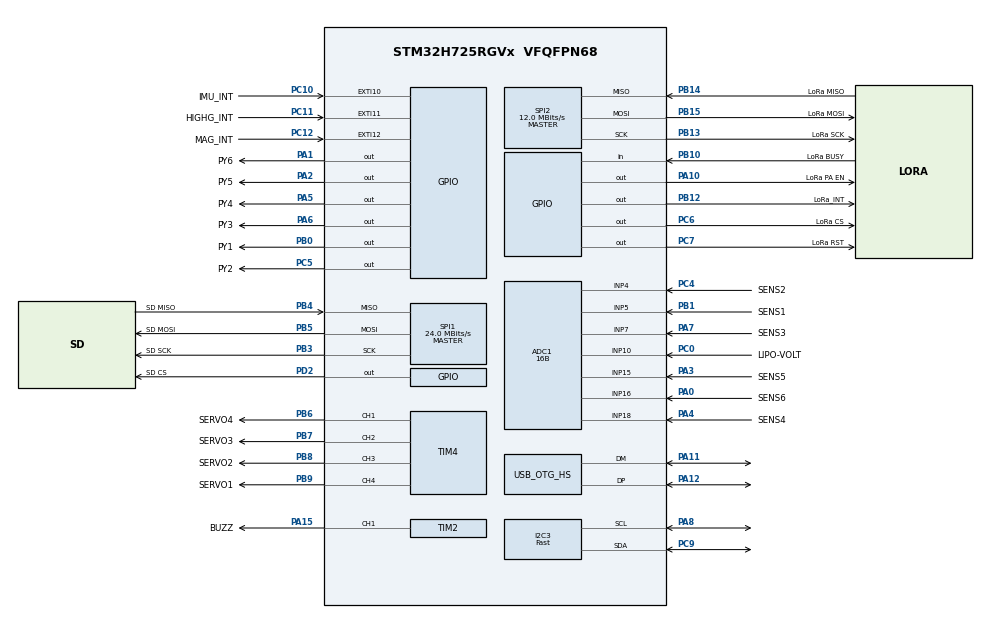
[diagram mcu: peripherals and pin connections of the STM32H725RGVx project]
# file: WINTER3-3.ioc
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ADC1.Channel-0\#ChannelRegularConversion=ADC_CHANNEL_10
ADC1.NbrOfConversionFlag=1
ADC1.OffsetNumber-0\#ChannelRegularConversion=ADC_OFFSET_NONE
ADC1.OffsetSignedSaturation-0\#ChannelRegularConversion=DISABLE
ADC1.Rank-0\#ChannelRegularConversion=1
ADC1.Resolution=ADC_RESOLUTION_16B
ADC1.SamplingTime-0\#ChannelRegularConversion=ADC_SAMPLETIME_64CYCLES_5
ADC1.master=1
CORTEX_M7.AccessPermission-Cortex_Memory_Protection_Unit_Region0_Settings=MPU_REGION_FULL_ACCESS
CORTEX_M7.AccessPermission-Cortex_Memory_Protection_Unit_Region1_Settings=MPU_REGION_FULL_ACCESS
CORTEX_M7.BaseAddress-Cortex_Memory_Protection_Unit_Region0_Settings=0x30000000
CORTEX_M7.BaseAddress-Cortex_Memory_Protection_Unit_Region1_Settings=0x38000000
CORTEX_M7.CPU_DCache=Enabled
CORTEX_M7.CPU_ICache=Enabled
CORTEX_M7.DisableExec-Cortex_Memory_Protection_Unit_Region0_Settings=MPU_INSTRUCTION_ACCESS_ENABLE
CORTEX_M7.Enable-Cortex_Memory_Protection_Unit_Region0_Settings=MPU_REGION_ENABLE
CORTEX_M7.Enable-Cortex_Memory_Protection_Unit_Region1_Settings=MPU_REGION_ENABLE
CORTEX_M7.MPU_Control=MPU_PRIVILEGED_DEFAULT
CORTEX_M7.Size-Cortex_Memory_Protection_Unit_Region0_Settings=MPU_REGION_SIZE_32KB
CORTEX_M7.Size-Cortex_Memory_Protection_Unit_Region1_Settings=MPU_REGION_SIZE_16KB
Dma.Request0=SPI1_TX
Dma.Request1=SPI1_RX
Dma.SPI1_RX.1.Direction=DMA_PERIPH_TO_MEMORY
Dma.SPI1_RX.1.EventEnable=DISABLE
Dma.SPI1_RX.1.FIFOMode=DMA_FIFOMODE_DISABLE
Dma.SPI1_RX.1.Instance=DMA1_Stream1
Dma.SPI1_RX.1.MemDataAlignment=DMA_MDATAALIGN_BYTE
Dma.SPI1_RX.1.MemInc=DMA_MINC_ENABLE
Dma.SPI1_RX.1.Mode=DMA_NORMAL
Dma.SPI1_RX.1.PeriphDataAlignment=DMA_PDATAALIGN_BYTE
Dma.SPI1_RX.1.PeriphInc=DMA_PINC_DISABLE
Dma.SPI1_RX.1.Polarity=HAL_DMAMUX_REQ_GEN_RISING
Dma.SPI1_RX.1.Priority=DMA_PRIORITY_HIGH
Dma.SPI1_RX.1.RequestNumber=1
Dma.SPI1_RX.1.SignalID=NONE
Dma.SPI1_RX.1.SyncEnable=DISABLE
Dma.SPI1_RX.1.SyncPolarity=HAL_DMAMUX_SYNC_NO_EVENT
Dma.SPI1_RX.1.SyncRequestNumber=1
Dma.SPI1_RX.1.SyncSignalID=NONE
Dma.SPI1_TX.0.Direction=DMA_MEMORY_TO_PERIPH
Dma.SPI1_TX.0.EventEnable=DISABLE
Dma.SPI1_TX.0.FIFOMode=DMA_FIFOMODE_DISABLE
Dma.SPI1_TX.0.Instance=DMA1_Stream0
Dma.SPI1_TX.0.MemDataAlignment=DMA_MDATAALIGN_BYTE
Dma.SPI1_TX.0.MemInc=DMA_MINC_ENABLE
Dma.SPI1_TX.0.Mode=DMA_NORMAL
Dma.SPI1_TX.0.PeriphDataAlignment=DMA_PDATAALIGN_BYTE
Dma.SPI1_TX.0.PeriphInc=DMA_PINC_DISABLE
Dma.SPI1_TX.0.Polarity=HAL_DMAMUX_REQ_GEN_RISING
Dma.SPI1_TX.0.Priority=DMA_PRIORITY_HIGH
Dma.SPI1_TX.0.RequestNumber=1
Dma.SPI1_TX.0.SignalID=NONE
Dma.SPI1_TX.0.SyncEnable=DISABLE
Dma.SPI1_TX.0.SyncPolarity=HAL_DMAMUX_SYNC_NO_EVENT
Dma.SPI1_TX.0.SyncRequestNumber=1
Dma.SPI1_TX.0.SyncSignalID=NONE
FATFS._FS_EXFAT=0
FATFS._FS_NORTC=1
FATFS._USE_EXPAND=1
FATFS._USE_LFN=2
I2C3.I2C_Speed_Mode=I2C_Fast
I2C3.Timing=0x00602173
Mcu.Family=STM32H7
Mcu.Name=STM32H725RGVx
Mcu.Package=VFQFPN68
NVIC.DMA1_Stream0_IRQn=true\:0\:0\:false\:false\:true\:false\:true\:true
NVIC.DMA1_Stream1_IRQn=true\:0\:0\:false\:false\:true\:false\:true\:true
NVIC.EXTI15_10_IRQn=true\:0\:0\:false\:false\:true\:true\:true\:true
NVIC.OTG_HS_EP1_IN_IRQn=true\:0\:0\:false\:false\:true\:true\:true\:true
NVIC.OTG_HS_EP1_OUT_IRQn=true\:0\:0\:false\:false\:true\:true\:true\:true
NVIC.OTG_HS_IRQn=true\:0\:0\:false\:false\:true\:false\:true\:true
NVIC.PriorityGroup=NVIC_PRIORITYGROUP_4
NVIC.SPI1_IRQn=true\:0\:0\:false\:false\:true\:false\:true\:true
PA0.GPIO_Label=SENS6
PA0.Mode=IN16-Single-Ended
PA0.Signal=ADC1_INP16
PA1.GPIO_Label=PY6
PA1.GPIO_PuPd=GPIO_NOPULL
PA1.Signal=GPIO_Output
PA10.GPIO_Label=LoRa PA EN
PA10.Signal=GPIO_Output
PA11.Mode=Device_Only_FS
PA11.Signal=USB_OTG_HS_DM
PA12.Mode=Device_Only_FS
PA12.Signal=USB_OTG_HS_DP
PA13(JTMS/SWDIO).GPIO_Label=SWDIO
PA13(JTMS/SWDIO).Mode=Serial_Wire
PA13(JTMS/SWDIO).Signal=DEBUG_JTMS-SWDIO
PA14(JTCK/SWCLK).GPIO_Label=SWCLK
PA14(JTCK/SWCLK).Mode=Serial_Wire
PA14(JTCK/SWCLK).Signal=DEBUG_JTCK-SWCLK
PA15(JTDI).GPIO_Label=BUZZ
PA15(JTDI).GPIO_Speed=GPIO_SPEED_FREQ_VERY_HIGH
PA15(JTDI).Signal=S_TIM2_CH1_ETR
PA2.GPIO_Label=PY5
PA2.GPIO_PuPd=GPIO_NOPULL
PA2.Signal=GPIO_Output
PA3.GPIO_Label=SENS5
PA3.Signal=ADCx_INP15
PA4.GPIO_Label=SENS4
PA4.Signal=ADCx_INP18
PA5.GPIO_Label=PY4
PA5.GPIO_PuPd=GPIO_NOPULL
PA5.Signal=GPIO_Output
PA6.GPIO_Label=PY3
PA6.GPIO_PuPd=GPIO_NOPULL
PA6.Signal=GPIO_Output
PA7.GPIO_Label=SENS3
PA7.Signal=ADCx_INP7
PA8.GPIO_Speed=GPIO_SPEED_FREQ_HIGH
PA8.Mode=I2C
PA8.Signal=I2C3_SCL
PB0.GPIO_Label=PY1
PB0.GPIO_PuPd=GPIO_NOPULL
PB0.Signal=GPIO_Output
PB1.GPIO_Label=SENS1
PB1.Signal=ADCx_INP5
PB10.GPIO_Label=LoRa BUSY
PB10.Signal=GPIO_Input
PB12.GPIO_Label=LoRa_INT
PB12.Signal=GPIO_Output
PB13.GPIO_Label=LoRa SCK
PB13.GPIO_Speed=GPIO_SPEED_FREQ_HIGH
PB13.Mode=Full_Duplex_Master
PB13.Signal=SPI2_SCK
PB14.GPIO_Label=LoRa MISO
PB14.GPIO_Speed=GPIO_SPEED_FREQ_HIGH
PB14.Mode=Full_Duplex_Master
PB14.Signal=SPI2_MISO
PB15.GPIO_Label=LoRa MOSI
PB15.GPIO_Speed=GPIO_SPEED_FREQ_HIGH
PB15.Mode=Full_Duplex_Master
PB15.Signal=SPI2_MOSI
PB3(JTDO/TRACESWO).GPIO_Label=SD SCK
PB3(JTDO/TRACESWO).GPIO_Speed=GPIO_SPEED_FREQ_HIGH
PB3(JTDO/TRACESWO).Mode=Full_Duplex_Master
PB3(JTDO/TRACESWO).Signal=SPI1_SCK
PB4(NJTRST).GPIO_Label=SD MISO
PB4(NJTRST).GPIO_Speed=GPIO_SPEED_FREQ_HIGH
PB4(NJTRST).Mode=Full_Duplex_Master
PB4(NJTRST).Signal=SPI1_MISO
PB5.GPIO_Label=SD MOSI
PB5.GPIO_Speed=GPIO_SPEED_FREQ_HIGH
PB5.Mode=Full_Duplex_Master
PB5.Signal=SPI1_MOSI
PB6.GPIO_Label=SERVO4
PB6.Signal=S_TIM4_CH1
PB7.GPIO_Label=SERVO3
PB7.Signal=S_TIM4_CH2
PB8.GPIO_Label=SERVO2
PB8.Signal=S_TIM4_CH3
PB9.GPIO_Label=SERVO1
PB9.Signal=S_TIM4_CH4
PC0.GPIO_Label=LIPO-VOLT
PC0.Signal=ADCx_INP10
PC10.GPIO_Label=IMU_INT
PC10.Signal=GPXTI10
PC11.GPIO_Label=HIGHG_INT
PC11.Signal=GPXTI11
PC12.GPIO_Label=MAG_INT
PC12.Signal=GPXTI12
PC4.GPIO_Label=SENS2
PC4.Signal=ADCx_INP4
PC5.GPIO_Label=PY2
PC5.GPIO_PuPd=GPIO_NOPULL
PC5.Signal=GPIO_Output
PC6.GPIO_Label=LoRa CS
PC6.GPIO_PuPd=GPIO_NOPULL
PC6.Signal=GPIO_Output
PC7.GPIO_Label=LoRa RST
PC7.Signal=GPIO_Output
PC9.GPIO_Speed=GPIO_SPEED_FREQ_HIGH
PC9.Mode=I2C
PC9.Signal=I2C3_SDA
PD2.GPIO_Label=SD CS
PD2.GPIO_PuPd=GPIO_NOPULL
PD2.GPIO_Speed=GPIO_SPEED_FREQ_HIGH
PD2.PinState=GPIO_PIN_SET
PD2.Signal=GPIO_Output
PH0-OSC_IN.Mode=HSE-External-Clock-Source
PH0-OSC_IN.Signal=RCC_OSC_IN
ProjectManager.HeapSize=0x200
ProjectManager.StackSize=0x400
ProjectManager.TargetToolchain=Makefile
RCC.ADCFreq_Value=48000000
RCC.APB1Freq_Value=120000000
RCC.APB2Freq_Value=120000000
RCC.APB3Freq_Value=120000000
RCC.APB4Freq_Value=120000000
RCC.CortexFreq_Value=240000000
RCC.D1PPRE=RCC_APB3_DIV2
RCC.D2PPRE1=RCC_APB1_DIV2
RCC.D2PPRE2=RCC_APB2_DIV2
RCC.D3PPRE=RCC_APB4_DIV2
RCC.DIVM1=2
RCC.DIVM2=2
RCC.DIVM3=2
RCC.DIVN1=20
RCC.DIVN2=16
RCC.DIVN3=16
RCC.DIVP1=1
RCC.DIVP2=4
RCC.DIVP3=1
RCC.DIVR3=3
RCC.HCLKFreq_Value=240000000
RCC.HSE_VALUE=24000000
RCC.I2C123CLockSelection=RCC_I2C1235CLKSOURCE_PLL3
RCC.PLL2FRACN=0
RCC.PLL3FRACN=0
RCC.PLLFRACN=0
RCC.PLLSourceVirtual=RCC_PLLSOURCE_HSE
RCC.SPI123CLockSelection=RCC_SPI123CLKSOURCE_PLL3
RCC.SYSCLKFreq_VALUE=240000000
RCC.SYSCLKSource=RCC_SYSCLKSOURCE_PLLCLK
RCC.USBCLockSelection=RCC_USBCLKSOURCE_HSI48
RCC.USBFreq_Value=48000000
SH.ADCx_INP10.0=ADC1_INP10,IN10-Single-Ended
SH.ADCx_INP15.0=ADC1_INP15,IN15-Single-Ended
SH.ADCx_INP18.0=ADC1_INP18,IN18-Single-Ended
SH.ADCx_INP4.0=ADC1_INP4,IN4-Single-Ended
SH.ADCx_INP5.0=ADC1_INP5,IN5-Single-Ended
SH.ADCx_INP7.0=ADC1_INP7,IN7-Single-Ended
SH.S_TIM2_CH1_ETR.0=TIM2_CH1,PWM Generation1 CH1
SH.S_TIM4_CH1.0=TIM4_CH1,PWM Generation1 CH1
SH.S_TIM4_CH2.0=TIM4_CH2,PWM Generation2 CH2
SH.S_TIM4_CH3.0=TIM4_CH3,PWM Generation3 CH3
SH.S_TIM4_CH4.0=TIM4_CH4,PWM Generation4 CH4
SPI1.BaudRatePrescaler=SPI_BAUDRATEPRESCALER_8
SPI1.CalculateBaudRate=24.0 MBits/s
SPI1.DataSize=SPI_DATASIZE_8BIT
SPI1.Direction=SPI_DIRECTION_2LINES
SPI1.Mode=SPI_MODE_MASTER
SPI1.VirtualType=VM_MASTER
SPI2.BaudRatePrescaler=SPI_BAUDRATEPRESCALER_16
SPI2.CalculateBaudRate=12.0 MBits/s
SPI2.DataSize=SPI_DATASIZE_8BIT
SPI2.Direction=SPI_DIRECTION_2LINES
SPI2.Mode=SPI_MODE_MASTER
SPI2.VirtualType=VM_MASTER
TIM2.Channel-PWM\ Generation1\ CH1=TIM_CHANNEL_1
TIM2.Period=999
TIM2.Prescaler=240
TIM2.Pulse-PWM\ Generation1\ CH1=500
TIM4.Channel-PWM\ Generation1\ CH1=TIM_CHANNEL_1
TIM4.Channel-PWM\ Generation2\ CH2=TIM_CHANNEL_2
TIM4.Channel-PWM\ Generation3\ CH3=TIM_CHANNEL_3
TIM4.Channel-PWM\ Generation4\ CH4=TIM_CHANNEL_4
USB_DEVICE.CLASS_NAME_HS=CDC
USB_DEVICE.USBD_LPM_ENABLED=0
USB_DEVICE.USBD_SELF_POWERED=0
USB_DEVICE.VirtualMode=Cdc
USB_DEVICE.VirtualModeHS=Cdc_HS
USB_OTG_HS.VirtualMode=Device_Only_FS
VP_CORDIC_VS_CORDIC.Mode=CORDIC_Activate
VP_FATFS_VS_Generic.Mode=User_defined
VP_FMAC_VS_FMAC.Mode=FMAC_Activate
VP_MEMORYMAP_VS_MEMORYMAP.Mode=CurAppReg
VP_TIM1_VS_ClockSourceINT.Mode=Internal
VP_TIM2_VS_ClockSourceINT.Mode=Internal
VP_USB_DEVICE_VS_USB_DEVICE_CDC_HS.Mode=CDC_HS
board=custom

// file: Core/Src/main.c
/* USER CODE BEGIN Header */
/**
 ******************************************************************************
 * @file           : main.c
 * @brief          : Main program body
 ******************************************************************************
 * @attention
 *
 * Copyright (c) 2025 STMicroelectronics.
 * All rights reserved.
 *
 * This software is licensed under terms that can be found in the LICENSE file
 * in the root directory of this software component.
 * If no LICENSE file comes with this software, it is provided AS-IS.
 *
 ******************************************************************************
 */
/* USER CODE END Header */
#include "main.h"
#include "adc.h"
#include "cordic.h"
#include "dma.h"
#include "fatfs.h"
#include "fmac.h"
#include "i2c.h"
#include "spi.h"
#include "tim.h"
#include "usb_device.h"
#include "gpio.h"

/* USER CODE BEGIN Includes */
#include "cpp_main.h"
/* USER CODE END Includes */

void SystemClock_Config(void);
void PeriphCommonClock_Config(void);
static void MPU_Config(void);

int main(void)
{

  /* MPU Configuration--------------------------------------------------------*/
  MPU_Config();

  /* Enable the CPU Cache */

  /* Enable I-Cache---------------------------------------------------------*/
  SCB_EnableICache();

  /* Enable D-Cache---------------------------------------------------------*/
  SCB_EnableDCache();

  /* MCU Configuration--------------------------------------------------------*/

  /* Reset of all peripherals, Initializes the Flash interface and the Systick. */
  HAL_Init();

  /* Configure the system clock */
  SystemClock_Config();

  /* Configure the peripherals common clocks */
  PeriphCommonClock_Config();

  /* Initialize all configured peripherals */
  MX_GPIO_Init();
  MX_DMA_Init();
  MX_CORDIC_Init();
  MX_FMAC_Init();
  MX_I2C3_Init();
  MX_SPI1_Init();
  MX_SPI2_Init();
  MX_TIM2_Init();
  MX_TIM4_Init();
  MX_ADC1_Init();
  MX_USB_DEVICE_Init();
  MX_FATFS_Init();
  MX_TIM1_Init();
  /* USER CODE BEGIN 2 */
  // 1. Enable the SYSCFG peripheral clock
  __HAL_RCC_SYSCFG_CLK_ENABLE();

  // 2. Map EXTI Line 4 to PORT B (0x01 maps to Port B)
  // Note: We use [1] because EXTICR[1] handles EXTI4, EXTI5, EXTI6, and EXTI7.
  SYSCFG->EXTICR[1] = (SYSCFG->EXTICR[1] & ~(0x0FU << 0)) | (0x01U << 0);

  // 3. Configure EXTI Line 4 to trigger on a RISING edge
  EXTI->RTSR1 |= EXTI_RTSR1_TR4;   // Enable rising edge trigger
  EXTI->FTSR1 &= ~EXTI_FTSR1_TR4;  // Disable falling edge trigger
  EXTI_D1->IMR1 |= EXTI_IMR1_IM4;  // Unmask EXTI4 in the Cortex-M7 domain

  // 4. Enable EXTI4 at the Core Level
  HAL_NVIC_SetPriority(EXTI4_IRQn, 5, 0);

  cpp_main();

  //should never pass this point

  /* USER CODE END 2 */

  /* Infinite loop */
  while (1)
  {

  }
}

void SystemClock_Config(void)
{
  RCC_OscInitTypeDef RCC_OscInitStruct = {0};
  RCC_ClkInitTypeDef RCC_ClkInitStruct = {0};

  /** Supply configuration update enable
  */
  HAL_PWREx_ConfigSupply(PWR_DIRECT_SMPS_SUPPLY);

  /** Configure the main internal regulator output voltage
  */
  __HAL_PWR_VOLTAGESCALING_CONFIG(PWR_REGULATOR_VOLTAGE_SCALE0);

  while(!__HAL_PWR_GET_FLAG(PWR_FLAG_VOSRDY)) {}

  /** Initializes the RCC Oscillators according to the specified parameters
  * in the RCC_OscInitTypeDef structure.
  */
  RCC_OscInitStruct.OscillatorType = RCC_OSCILLATORTYPE_HSI48|RCC_OSCILLATORTYPE_HSE;
  RCC_OscInitStruct.HSEState = RCC_HSE_BYPASS;
  RCC_OscInitStruct.HSI48State = RCC_HSI48_ON;
  RCC_OscInitStruct.PLL.PLLState = RCC_PLL_ON;
  RCC_OscInitStruct.PLL.PLLSource = RCC_PLLSOURCE_HSE;
  RCC_OscInitStruct.PLL.PLLM = 2;
  RCC_OscInitStruct.PLL.PLLN = 20;
  RCC_OscInitStruct.PLL.PLLP = 1;
  RCC_OscInitStruct.PLL.PLLQ = 2;
  RCC_OscInitStruct.PLL.PLLR = 2;
  RCC_OscInitStruct.PLL.PLLRGE = RCC_PLL1VCIRANGE_3;
  RCC_OscInitStruct.PLL.PLLVCOSEL = RCC_PLL1VCOWIDE;
  RCC_OscInitStruct.PLL.PLLFRACN = 0;
  if (HAL_RCC_OscConfig(&RCC_OscInitStruct) != HAL_OK)
  {
    Error_Handler();
  }

  /** Initializes the CPU, AHB and APB buses clocks
  */
  RCC_ClkInitStruct.ClockType = RCC_CLOCKTYPE_HCLK|RCC_CLOCKTYPE_SYSCLK
                              |RCC_CLOCKTYPE_PCLK1|RCC_CLOCKTYPE_PCLK2
                              |RCC_CLOCKTYPE_D3PCLK1|RCC_CLOCKTYPE_D1PCLK1;
  RCC_ClkInitStruct.SYSCLKSource = RCC_SYSCLKSOURCE_PLLCLK;
  RCC_ClkInitStruct.SYSCLKDivider = RCC_SYSCLK_DIV1;
  RCC_ClkInitStruct.AHBCLKDivider = RCC_HCLK_DIV1;
  RCC_ClkInitStruct.APB3CLKDivider = RCC_APB3_DIV2;
  RCC_ClkInitStruct.APB1CLKDivider = RCC_APB1_DIV2;
  RCC_ClkInitStruct.APB2CLKDivider = RCC_APB2_DIV2;
  RCC_ClkInitStruct.APB4CLKDivider = RCC_APB4_DIV2;

  if (HAL_RCC_ClockConfig(&RCC_ClkInitStruct, FLASH_LATENCY_3) != HAL_OK)
  {
    Error_Handler();
  }
}

void PeriphCommonClock_Config(void)
{
  RCC_PeriphCLKInitTypeDef PeriphClkInitStruct = {0};

  /** Initializes the peripherals clock
  */
  PeriphClkInitStruct.PeriphClockSelection = RCC_PERIPHCLK_I2C3|RCC_PERIPHCLK_SPI2
                              |RCC_PERIPHCLK_SPI1;
  PeriphClkInitStruct.PLL3.PLL3M = 2;
  PeriphClkInitStruct.PLL3.PLL3N = 16;
  PeriphClkInitStruct.PLL3.PLL3P = 1;
  PeriphClkInitStruct.PLL3.PLL3Q = 2;
  PeriphClkInitStruct.PLL3.PLL3R = 3;
  PeriphClkInitStruct.PLL3.PLL3RGE = RCC_PLL3VCIRANGE_3;
  PeriphClkInitStruct.PLL3.PLL3VCOSEL = RCC_PLL3VCOWIDE;
  PeriphClkInitStruct.PLL3.PLL3FRACN = 0;
  PeriphClkInitStruct.Spi123ClockSelection = RCC_SPI123CLKSOURCE_PLL3;
  PeriphClkInitStruct.I2c123ClockSelection = RCC_I2C1235CLKSOURCE_PLL3;
  if (HAL_RCCEx_PeriphCLKConfig(&PeriphClkInitStruct) != HAL_OK)
  {
    Error_Handler();
  }
}

 /* MPU Configuration */

void MPU_Config(void)
{
  MPU_Region_InitTypeDef MPU_InitStruct = {0};

  /* Disables the MPU */
  HAL_MPU_Disable();

  /** Initializes and configures the Region and the memory to be protected
  */
  MPU_InitStruct.Enable = MPU_REGION_ENABLE;
  MPU_InitStruct.Number = MPU_REGION_NUMBER0;
  MPU_InitStruct.BaseAddress = 0x30000000;
  MPU_InitStruct.Size = MPU_REGION_SIZE_32KB;
  MPU_InitStruct.SubRegionDisable = 0x0;
  MPU_InitStruct.TypeExtField = MPU_TEX_LEVEL0;
  MPU_InitStruct.AccessPermission = MPU_REGION_FULL_ACCESS;
  MPU_InitStruct.DisableExec = MPU_INSTRUCTION_ACCESS_ENABLE;
  MPU_InitStruct.IsShareable = MPU_ACCESS_NOT_SHAREABLE;
  MPU_InitStruct.IsCacheable = MPU_ACCESS_NOT_CACHEABLE;
  MPU_InitStruct.IsBufferable = MPU_ACCESS_NOT_BUFFERABLE;

  HAL_MPU_ConfigRegion(&MPU_InitStruct);

  /** Initializes and configures the Region and the memory to be protected
  */
  MPU_InitStruct.Number = MPU_REGION_NUMBER1;
  MPU_InitStruct.BaseAddress = 0x38000000;
  MPU_InitStruct.Size = MPU_REGION_SIZE_16KB;

  HAL_MPU_ConfigRegion(&MPU_InitStruct);
  /* Enables the MPU */
  HAL_MPU_Enable(MPU_PRIVILEGED_DEFAULT);

}

void Error_Handler(void)
{
  __disable_irq();
  while (1)
  {
  }
}
